VERSION ""

NS_ :

BS_:

BU_: ECU PAINEL RES JETSON DATALOGGER

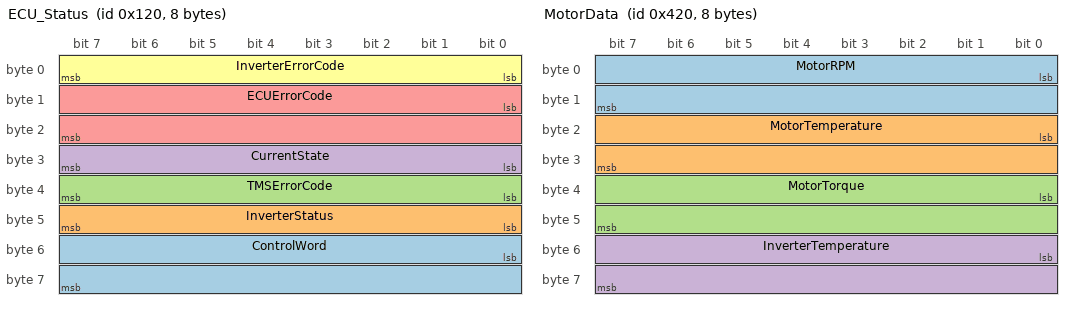
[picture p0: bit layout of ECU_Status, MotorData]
BO_ 288 ECU_Status: 8 ECU
 SG_ ControlWord : 48|16@1+ (1,0) [0|0] ""  JETSON,DATALOGGER
 SG_ InverterStatus : 40|8@1+ (1,0) [0|0] ""  JETSON,DATALOGGER
 SG_ TMSErrorCode : 32|8@1+ (1,0) [0|0] ""  JETSON,DATALOGGER
 SG_ CurrentState : 24|8@1+ (1,0) [0|0] ""  JETSON,DATALOGGER
 SG_ ECUErrorCode : 8|16@1+ (1,0) [0|0] ""  JETSON,DATALOGGER
 SG_ InverterErrorCode : 0|8@1+ (1,0) [0|0] ""  JETSON,DATALOGGER

BO_ 1056 MotorData: 8 ECU
 SG_ MotorRPM : 0|16@1+ (1,0) [0|0] "RPM"  DATALOGGER,JETSON
 SG_ MotorTemperature : 16|16@1+ (1,0) [0|0] "degC"  DATALOGGER,JETSON
 SG_ MotorTorque : 32|16@1+ (1,0) [0|0] "Nm"  DATALOGGER,JETSON
 SG_ InverterTemperature : 48|16@1+ (1,0) [0|0] "degC"  DATALOGGER,JETSON

BO_ 544 CurrentData: 8 ECU
 SG_ InverterCurrent : 0|32@1- (0.1,0) [0|0] "A"  DATALOGGER,JETSON
 SG_ BatteryCurrent : 32|32@1- (0.1,0) [0|0] "A"  DATALOGGER,JETSON

BO_ 1057 VoltageData: 8 ECU
 SG_ InverterVoltage : 0|32@1- (0.1,0) [0|0] "V"  DATALOGGER,JETSON
 SG_ BatteryVoltage : 32|32@1- (0.1,0) [0|0] "V"  DATALOGGER,JETSON

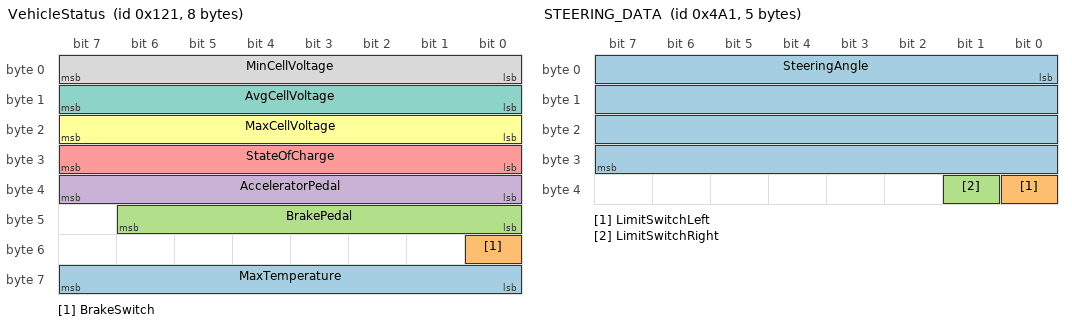
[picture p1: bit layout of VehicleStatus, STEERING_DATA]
BO_ 289 VehicleStatus: 8 ECU
 SG_ MaxTemperature : 56|8@1+ (1,0) [0|0] "degC"  DATALOGGER,JETSON
 SG_ BrakeSwitch : 48|1@1+ (1,0) [0|0] ""  DATALOGGER,JETSON
 SG_ BrakePedal : 40|7@1+ (1,0) [0|0] "%"  DATALOGGER,JETSON
 SG_ AcceleratorPedal : 32|8@1+ (1,0) [0|0] "%"  DATALOGGER,JETSON
 SG_ StateOfCharge : 24|8@1+ (1,0) [0|0] "%"  DATALOGGER,JETSON
 SG_ MaxCellVoltage : 16|8@1+ (10,0) [0|0] "mV"  DATALOGGER,JETSON
 SG_ AvgCellVoltage : 8|8@1+ (10,0) [0|0] "mV"  DATALOGGER,JETSON
 SG_ MinCellVoltage : 0|8@1+ (10,0) [0|0] "mV"  DATALOGGER,JETSON

BO_ 321 PAINEL_RTD: 1 PAINEL
 SG_ ReadyToDrive : 0|1@1+ (1,0) [0|0] "" Vector__XXX

BO_ 839 PAINEL_MODE: 1 PAINEL
 SG_ AutonomousMode : 0|3@1+ (1,0) [0|0] ""  DATALOGGER,JETSON

BO_ 1355 PAINEL__PAGE: 1 PAINEL
 SG_ PageID : 0|4@1+ (1,0) [0|0] ""  DATALOGGER,JETSON

BO_ 1185 STEERING_DATA: 5 DATALOGGER
 SG_ SteeringAngle : 0|32@1- (0.1,0) [0|0] "deg"  JETSON
 SG_ LimitSwitchLeft : 32|1@1+ (1,0) [0|0] ""  JETSON
 SG_ LimitSwitchRight : 33|1@1+ (1,0) [0|0] ""  JETSON

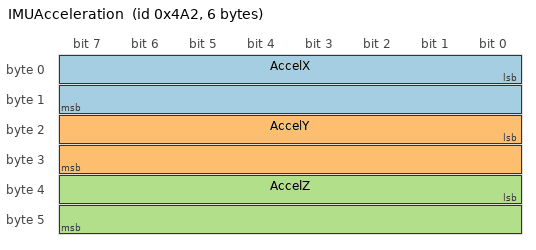
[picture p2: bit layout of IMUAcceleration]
BO_ 1186 IMUAcceleration: 6 DATALOGGER
 SG_ AccelX : 0|16@1- (0.001,0) [0|0] "m/s²"  JETSON
 SG_ AccelY : 16|16@1- (0.001,0) [0|0] "m/s²"  JETSON
 SG_ AccelZ : 32|16@1- (0.001,0) [0|0] "m/s²"  JETSON

BO_ 1187 RearWheelEncoders: 8 DATALOGGER
 SG_ EncoderRearLeft : 32|32@1- (1,0) [0|0] "km/h"  JETSON
 SG_ EncoderRearRight : 0|32@1- (1,0) [0|0] "km/h"  JETSON

BO_ 1188 FrontWheelEncoders: 8 DATALOGGER
 SG_ EncoderFrontRight : 0|32@1- (1,0) [0|0] "km/h"  JETSON
 SG_ EncoderFrontLeft : 32|32@1- (1,0) [0|0] "km/h"  JETSON

BO_ 393 RESControl: 8 RES
 SG_ ASStatus : 0|8@1+ (1,0) [0|0] ""  JETSON
 SG_ GOSignal : 8|8@1+ (1,0) [0|0] ""  JETSON

BO_ 865 Jetson: 8 JETSON
 SG_ AutonomousModeJetson : 0|8@1+ (1,0) [0|0] "" Vector__XXX

BO_ 137 RESEmergency: 8 RES
 SG_ ASEmergency : 0|1@1+ (1,0) [0|0] ""  JETSON

BO_ 3221225472 VECTOR__INDEPENDENT_SIG_MSG: 0 Vector__XXX
 SG_ a : 0|1@1+ (1,0) [0|0] ""  DATALOGGER,JETSON

CM_ BU_ ECU "Main controller";
CM_ BO_ 288 "10 Hz";
CM_ BO_ 1056 "10 Hz";
CM_ BO_ 544 "10 Hz";
CM_ BO_ 1057 "10 Hz";
CM_ BO_ 289 "10 Hz";
CM_ BO_ 321 "5 Hz
";
CM_ BO_ 839 "5 Hz

";
CM_ BO_ 1355 "5 Hz
";
CM_ BO_ 1185 "60 Hz
";
CM_ BO_ 1186 "60 Hz
";
CM_ BO_ 1187 "60 Hz
";
CM_ BO_ 1188 "60 Hz
";
CM_ BO_ 393 "100 Hz";
CM_ BO_ 865 "10 Hz";
CM_ BO_ 137 "100 Hz
";
BA_DEF_  "BusType" STRING ;
BA_DEF_DEF_  "BusType" "CAN";
VAL_ 288 CurrentState 0 "HV_OFF" 1 "NOT_RTD" 2 "ALMOST_RTD" 3 "RTD" ;
VAL_ 288 ECUErrorCode 0 "NoError" 1 "DefinedErrors" ;
VAL_ 288 InverterErrorCode 0 "NoError" 1 "DefinedErrors" ;
VAL_ 289 BrakeSwitch 0 "Released" 1 "Pressed" ;
VAL_ 839 AutonomousMode 1 "CHECK" 2 "CALIBRATION" 3 "TRACKDRIVE" 4 "SKIDPAD" 5 "ACCELERATION" 6 "AUTOCROSS" 7 "Start 
INSPEÇÃO

" ;
VAL_ 1355 PageID 0 "Capa" 1 "TestesElétrica" 2 "ModoDeProva" 3 "MenuSA" 4 "TestesSA" 5 "AutoCrossSA" 6 "AceleraçãoSA" 7 "SkidpadSA" 8 "TrackDriveSA" 9 "TesteEBS" 10 "InspeçãoSA" ;
VAL_ 1185 LimitSwitchLeft 0 "Released" 1 "Pressed" ;
VAL_ 1185 LimitSwitchRight 0 "Released" 1 "Pressed" ;
VAL_ 3221225472 a 0 "Disabled" 1 "Enabled" ;
SIG_VALTYPE_ 544 InverterCurrent : 1;
SIG_VALTYPE_ 544 BatteryCurrent : 1;
SIG_VALTYPE_ 1057 InverterVoltage : 1;
SIG_VALTYPE_ 1057 BatteryVoltage : 1;
SIG_VALTYPE_ 1185 SteeringAngle : 1;
SIG_VALTYPE_ 1187 EncoderRearLeft : 1;
SIG_VALTYPE_ 1187 EncoderRearRight : 1;
SIG_VALTYPE_ 1188 EncoderFrontRight : 1;
SIG_VALTYPE_ 1188 EncoderFrontLeft : 1;
